# LPC18xx register map
File version: 18
Registers are 32-bit, read-write, reset 0x0 unless marked. A register's access mark holds for its fields unless they carry their own. Offsets are from the block's base; [hi:lo] are bit positions; {n}, {i} and the like mark numbered series; 'fields as' and 'values as' point back to an identical list.

## USB0 (part 2 of 2) — Product name title=UM10430 Chapter title=LPC18xx USB0 Host/Device/OTG controller Modification date=1/19/2011 Major revision=0 Minor revision=7
Base 0x40006000
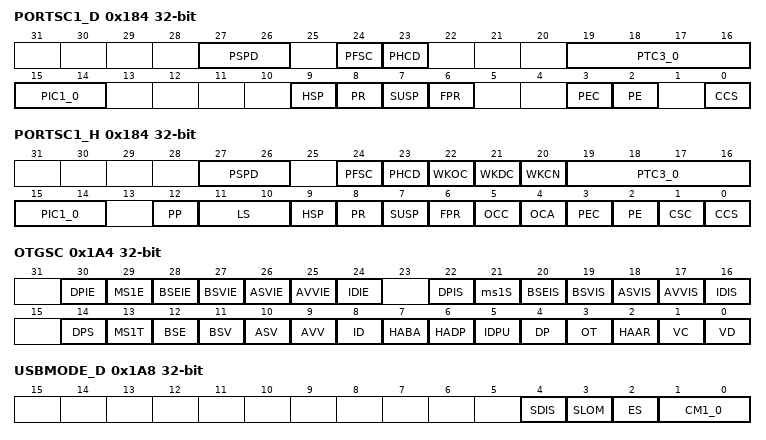
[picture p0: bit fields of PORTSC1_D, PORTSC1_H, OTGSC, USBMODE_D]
0x184 PORTSC1_D — Port 1 status/control (device mode)
  [27:26] PSPD — Port speed This register field indicates the speed at which the port is operating.
    0=FULL_SPEED; 1=INVALID_IN_DEVICE_MO (invalid in device mode); 2=HIGH_SPEED
  [24] PFSC — Port force full speed connect
    0=ANYSPEED (Port connects at any speed.); 1=FULLSPEED (Writing this bit to a 1 will force the port to only connect at full speed. It disables the chirp sequence that allows the port to identify itself as High-speed. This is useful for testing FS configurations with a HS host, hub or device.)
  [23] PHCD — PHY low power suspend - clock disable (PLPSCD) In device mode, The PHY can be put into Low Power Suspend - Clock Disable when the device is not running (USBCMD Run/Stop = 0) or the host has signaled suspend (PORTSC SUSPEND = 1). Low power suspend will be cleared automatically when the host has signaled resume. Before forcing a resume from the device, the device controller driver must clear this bit.
    0=ENABLE (Writing a 0 enables the PHY clock. Reading a 0 indicates the status of the PHY clock (enabled).); 1=DISABLE (Writing a 1 disables the PHY clock. Reading a 1 indicates the status of the PHY clock (disabled).)
  [19:16] PTC3_0 — Port test control Any value other than 0000 indicates that the port is operating in test mode. The FORCE_ENABLE_FS and FORCE ENABLE_LS are extensions to the test mode support specified in the EHCI specification. Writing the PTC field to any of the FORCE_ENABLE_HS/FS/LS values will force the port into the connected and enabled state at the selected speed. Writing the PTC field back to TEST_MODE_DISABLE will allow the port state machines to progress normally from that point. Values 0111 to 1111 are not valid.
    0=TEST_MODE_DISABLE; 1=J_STATE; 2=K_STATE; 3=SE0_(HOST)/NAK_(DEVI (SE0 (host)/NAK (device)); 4=PACKET; 5=FORCE_ENABLE_HS; 6=FORCE_ENABLE_FS
  [15:14] PIC1_0 — Port indicator control Writing to this field effects the value of the USB0_IND[1:0] pins.
    0=OFF (Port indicators are off.); 1=AMBER; 2=GREEN; 3=UNDEFINED
  [9] HSP — High-speed status This bit is redundant with bits 27:26 (PSPD) in this register. It is implemented for compatibility reasons.
    0=NOT_HIGHSSPEED (Host/device connected to the port is not in High-speed mode.); 1=HIGHSPEED (Host/device connected to the port is in High-speed mode.)
  [8] PR — Port reset In device mode, this is a read-only status bit. A device reset from the USB bus is also indicated in the USBSTS register.
    0=PORT_IS_NOT_IN_THE_R (Port is not in the reset state.); 1=PORT_IS_IN_THE_RESET (Port is in the reset state.)
  [7] SUSP — Suspend In device mode, this is a read-only status bit .
    0=PORT_NOT_IN_SUSPEND_ (Port not in suspend state); 1=PORT_IN_SUSPEND_STAT (Port in suspend state)
  [6] FPR — Force port resume After the device has been in Suspend State for 5 ms or more, software must set this bit to one to drive resume signaling before clearing. The Device Controller will set this bit to one if a J-to-K transition is detected while the port is in the Suspend state. The bit will be cleared when the device returns to normal operation. When this bit transitions to a one because a J-to-K transition detected, the Port Change Detect bit in the USBSTS register is set to one as well.
    0=NO_RESUME_(K_STATE)_ (No resume (K-state) detected/driven on port.); 1=RESUME_DETECTED/DRIV (Resume detected/driven on port.)
  [3] PEC — Port enable/disable change This bit is always 0. The device port is always enabled.
  [2] PE — Port enable. This bit is always 1. The device port is always enabled.
  [0] CCS — Current connect status
    0=DEVICE_NOT_ATTACHED_ (Device not attached A zero indicates that the device did not attach successfully or was forcibly disconnected by the software writing a zero to the Run bit in the USBCMD register. It does not state the device being disconnected or suspended.); 1=DEVICE_ATTACHED__A_ (Device attached. A one indicates that the device successfully attached and is operating in either high-speed mode or full-speed mode as indicated by the High Speed Port bit in this register.)
0x184 PORTSC1_H (alternate view of PORTSC1_D) — Port 1 status/control (host mode)
  [27:26] PSPD — Port speed This register field indicates the speed at which the port is operating. For HS mode operation in the host controller and HS/FS operation in the device controller the port routing steers data to the Protocol engine. For FS and LS mode operation in the host controller, the port routing steers data to the Protocol Engine w/ Embedded Transaction Translator.
    0=FULL_SPEED; 1=LOW_SPEED; 2=HIGH_SPEED
  [24] PFSC — Port force full speed connect
    0=PORT_CONNECTS_AT_ANY (Port connects at any speed.); 1=WRITING_THIS_BIT_TO_ (Writing this bit to a 1 will force the port to only connect at Full Speed. It disables the chirp sequence that allows the port to identify itself as High Speed. This is useful for testing FS configurations with a HS host, hub or device.)
  [23] PHCD — PHY low power suspend - clock disable (PLPSCD) In host mode, the PHY can be put into Low Power Suspend - Clock Disable when the downstream device has been put into suspend mode or when no downstream device is connected. Low power suspend is completely under the control of software.
    0=WRITING_A_0_ENABLES_ (Writing a 0 enables the PHY clock. Reading a 0 indicates the status of the PHY clock (enabled).); 1=WRITING_A_1_DISABLES (Writing a 1 disables the PHY clock. Reading a 1 indicates the status of the PHY clock (disabled).)
  [22] WKOC — Wake on over-current enable (WKOC_E)
    0=DISABLES_THE_PORT_TO (Disables the port to wake up on over-current events.); 1=WRITING_A_ONE_TO_THI (Writing a one to this bit enabled the port to be sensitive to over-current conditions as wake-up events.)
  [21] WKDC — Wake on disconnect enable (WKDSCNNT_E) This bit is 0 if PP (Port Power bit) is 0.
    0=DISABLES_THE_PORT_TO (Disables the port to wake up on device disconnects.); 1=WRITING_THIS_BIT_TO_ (Writing this bit to a one enables the port to be sensitive to device disconnects as wake-up events.)
  [20] WKCN — Wake on connect enable (WKCNNT_E) This bit is 0 if PP (Port Power bit) is 0
    0=DISABLES_THE_PORT_TO (Disables the port to wake up on device connects.); 1=WRITING_THIS_BIT_TO_ (Writing this bit to a one enables the port to be sensitive to device connects as wake-up events.)
  [19:16] PTC3_0 — Port test control Any value other than 0000 indicates that the port is operating in test mode. The FORCE_ENABLE_FS and FORCE ENABLE_LS are extensions to the test mode support specified in the EHCI specification. Writing the PTC field to any of the FORCE_ENABLE_{HS/FS/LS} values will force the port into the connected and enabled state at the selected speed. Writing the PTC field back to TEST_MODE_DISABLE will allow the port state machines to progress normally from that point. Values 0x8 to 0xF are reserved.
    0=TEST_MODE_DISABLE; 1=J_STATE; 2=K_STATE; 3=SE0_(HOST)/NAK_(DEVI (SE0 (host)/NAK (device)); 4=PACKET; 5=FORCE_ENABLE_HS; 6=FORCE_ENABLE_FS; 7=FORCE_ENABLE_LS
  [15:14] PIC1_0 — Port indicator control Writing to this field effects the value of the pins USB0_IND1 and USB0_IND0.
    0=PORT_INDICATORS_ARE_ (Port indicators are off.); 1=AMBER; 2=GREEN; 3=UNDEFINED
  [12] PP — Port power control Host/OTG controller requires port power control switches. This bit represents the current setting of the switch (0=off, 1=on). When power is not available on a port (i.e. PP equals a 0), the port is non-functional and will not report attaches, detaches, etc. When an over-current condition is detected on a powered port and PPC is a one, the PP bit in each affected port may be transitioned by the host controller driver from a one to a zero (removing power from the port).
    0=PORT_POWER_OFF_; 1=PORT_POWER_ON_
  [11:10] LS — Line status These bits reflect the current logical levels of the USB_DP and USB_DM signal lines. USB_DP corresponds to bit 11 and USB_DM to bit 10. In host mode, the use of linestate by the host controller driver is not necessary for this controller (unlike EHCI) because the controller hardware manages the connection of LS and FS.
    0=SE0_(USB_DP_AND_USB_ (SE0 (USB_DP and USB_DM LOW)); 1=J_STATE_(USB_DP_HIGH (J-state (USB_DP HIGH and USB_DM LOW)); 2=K_STATE_(USB_DP_LOW_ (K-state (USB_DP LOW and USB_DM HIGH)); 3=UNDEFINED
  [9] HSP — High-speed status
    0=HOST/DEVICE_CONNECTE (Host/device connected to the port is not in High-speed mode.); 1=HOST/DEVICE_CONNECTE (Host/device connected to the port is in High-speed mode.)
  [8] PR — Port reset When software writes a one to this bit the bus-reset sequence as defined in the USB Specification Revision 2.0 is started. This bit will automatically change to zero after the reset sequence is complete. This behavior is different from EHCI where the host controller driver is required to set this bit to a zero after the reset duration is timed in the driver. This bit is 0 if PP (Port Power bit) is 0.
    values as PORTSC1_D.PR
  [7] SUSP — Suspend Together with the PE (Port enabled bit), this bit describes the port states, see Table 240. The host controller will unconditionally set this bit to zero when software sets the Force Port Resume bit to zero. The host controller ignores a write of zero to this bit. If host software sets this bit to a one when the port is not enabled (i.e. Port enabled bit is a zero) the results are undefined. This bit is 0 if PP (Port Power bit) is 0.
    0=PORT_NOT_IN_SUSPEND_ (Port not in suspend state); 1=PORT_IN_SUSPEND_STAT (Port in suspend state When in suspend state, downstream propagation of data is blocked on this port, except for port reset. The blocking occurs at the end of the current transaction if a transaction was in progress when this bit was written to 1. In the suspend state, the port is sensitive to resume detection. Note that the bit status does not change until the port is suspended and that there may be a delay in suspending a port if there is a transaction currently in progress on the USB.)
  [6] FPR — Force port resume Software sets this bit to one to drive resume signaling. The Host Controller sets this bit to one if a J-to-K transition is detected while the port is in the Suspend state. When this bit transitions to a one because a J-to-K transition is detected, the Port Change Detect bit in the USBSTS register is also set to one. This bit will automatically change to zero after the resume sequence is complete. This behavior is different from EHCI where the host controller driver is required to set this bit to a zero after the resume duration is timed in the driver. Note that when the Host controller owns the port, the resume sequence follows the defined sequence documented in the USB Specification Revision 2.0. The resume signaling (Full-speed K) is driven on the port as long as this bit remains a one. This bit will remain a one until the port has switched to the high-speed idle. Writing a zero has no affect because the port controller will time the resume operation clear the bit the port control state switches to HS or FS idle. This bit is 0 if PP (Port Power bit) is 0.
    values as PORTSC1_D.FPR
  [5] OCC — Over-current change This bit gets set to one when there is a change to Over-current Active. Software clears this bit by writing a one to this bit position.
  [4] OCA — Over-current active This bit will automatically transition from 1 to 0 when the over-current condition is removed.
    0=THE_PORT_DOES_NOT_HA (The port does not have an over-current condition.); 1=THE_PORT_HAS_CURRENT (The port has currently an over-current condition.)
  [3] PEC — Port disable/enable change For the root hub, this bit gets set to a one only when a port is disabled due to disconnect on the port or due to the appropriate conditions existing at the EOF2 point (See Chapter 11 of the USB Specification). Software clears this by writing a one to it. This bit is 0 if PP (Port Power bit) is 0,
    0=NO_CHANGE_; 1=PORT_ENABLED/DISABLE (Port enabled/disabled status has changed.)
  [2] PE — Port enable. Ports can only be enabled by the host controller as a part of the reset and enable. Software cannot enable a port by writing a one to this field. Ports can be disabled by either a fault condition (disconnect event or other fault condition) or by the host software. Note that the bit status does not change until the port state actually changes. There may be a delay in disabling or enabling a port due to other host controller and bus events. When the port is disabled. downstream propagation of data is blocked except for reset. This bit is 0 if PP (Port Power bit) is 0.
    0=PORT_DISABLED_; 1=PORT_ENABLED_
  [1] CSC — Connect status change Indicates a change has occurred in the port's Current Connect Status. The host/device controller sets this bit for all changes to the port device connect status, even if system software has not cleared an existing connect status change. For example, the insertion status changes twice before system software has cleared the changed condition, hub hardware will be setting an already-set bit (i.e., the bit will remain set). Software clears this bit by writing a one to it. This bit is 0 if PP (Port Power bit) is 0
    0=NO_CHANGE_IN_CURRENT (No change in current status.); 1=CHANGE_IN_CURRENT_ST (Change in current status.)
  [0] CCS — Current connect status This value reflects the current state of the port and may not correspond directly to the event that caused the CSC bit to be set. This bit is 0 if PP (Port Power bit) is 0. Software clears this bit by writing a 1 to it.
    0=NO_DEVICE_IS_PRESENT; 1=DEVICE_IS_PRESENT_ON (Device is present on the port.)
0x1A4 OTGSC — OTG status and control
  [30] DPIE — Data pulse interrupt enable Setting this bit enables the data pulse interrupt. Writing a 0 disables the interrupt
  [29] MS1E — 1 millisecond timer interrupt enable Setting this bit enables the 1 millisecond timer interrupt. Writing a 0 disables the interrupt.
  [28] BSEIE — B-session end interrupt enable Setting this bit enables the B-session end interrupt. Writing a 0 disables the interrupt.
  [27] BSVIE — B-session valid interrupt enable Setting this bit enables the B-session valid interrupt. Writing a 0 disables the interrupt.
  [26] ASVIE — A-session valid interrupt enable Setting this bit enables the A-session valid interrupt. Writing a 0 disables the interrupt
  [25] AVVIE — A-VBUS valid interrupt enable Setting this bit enables the A-VBUS valid interrupt. Writing a 0 disables the interrupt.
  [24] IDIE — USB ID interrupt enable Setting this bit enables the interrupt. Writing a 0 disables the interrupt.
  [22] DPIS — Data pulse interrupt status This bit is set when data bus pulsing occurs on DP or DM. Data bus pulsing is only detected when the CM bit in USBMODE = Host (11) and the PortPower bit in PORTSC = Off (0). Software must write a 1 to this bit to clear it.
  [21] ms1S — 1 millisecond timer interrupt status This bit is set once every millisecond. Software must write a 1 to this bit to clear it.
  [20] BSEIS — B-Session end interrupt status This bit is set then VBUS has fallen below the B-session end threshold. Software must write a 1 to this bit to clear it.
  [19] BSVIS — B-Session valid interrupt status This bit is set then VBUS has either risen above or fallen below the B-session valid threshold (0.8 V). Software must write a 1 to this bit to clear it.
  [18] ASVIS — A-Session valid interrupt status This bit is set then VBUS has either risen above or fallen below the A-session valid threshold (0.8 V). Software must write a 1 to this bit to clear it.
  [17] AVVIS — A-VBUS valid interrupt status This bit is set then VBUS has either risen above or fallen below the A-VBUS valid threshold (4.4 V on an A-device). Software must write a 1 to this bit to clear it.
  [16] IDIS — USB ID interrupt status This bit is set when a change on the ID input has been detected. Software must write a 1 to this bit to clear it.
  [14] DPS — Data bus pulsing status Reading a 1 indicates that data bus pulsing is detected on the port.
  [13] MS1T — 1 millisecond timer toggle This bit toggles once per millisecond.
  [12] BSE — B-session end Reading 1 indicates that VBUS is below the B-session end threshold.
  [11] BSV — B-session valid Reading 1 indicates that VBUS is above the B-session valid threshold.
  [10] ASV — A-session valid Reading 1 indicates that VBUS is above the A-session valid threshold.
  [9] AVV — A-VBUS valid Reading 1 indicates that VBUS is above the A-VBUS valid threshold.
  [8] ID — USB ID
    0=A_DEVICE; 1=B_DEVICE
  [7] HABA — Hardware assist B-disconnect to A-connect
    0=DISABLED_; 1=ENABLE_AUTOMATIC_B_D (Enable automatic B-disconnect to A-connect sequence.)
  [6] HADP — Hardware assist data pulse Write a 1 to start data pulse sequence.
  [5] IDPU — ID pull-up. This bit provides control over the pull-up resistor.
    0=PULL_UP_OFF_THE_ID_ (Pull-up off. The ID bit will not be sampled.); 1=PULL_UP_ON_
  [4] DP — Data pulsing Setting this bit to 1 causes the pull-up on USB_DP to be asserted for data pulsing during SRP.
  [3] OT — OTG termination This bit must be set to 1 when the OTG controller is in device mode. This controls the pull-down on USB_DM.
  [2] HAAR — Hardware assist auto_reset
    0=DISABLED; 1=ENABLE_AUTOMATIC_RES (Enable automatic reset after connect on host port.)
  [1] VC — VBUS_Charge Setting this bit to 1 causes the VBUS line to be charged. This is used for VBUS pulsing during SRP.
  [0] VD — VBUS_Discharge Setting this bit to 1 causes VBUS to discharge through a resistor.
0x1A8 USBMODE_D — USB device mode (device mode)
  [4] SDIS — Stream disable mode The use of this feature substantially limits the overall USB performance that can be achieved.
    0=NOT_DISABLED; 1=DISABLED_SETTING_TH (Disabled. Setting this bit to one disables double priming on both RX and TX for low bandwidth systems. This mode ensures that when the RX and TX buffers are sufficient to contain an entire packet that the standard double buffering scheme is disabled to prevent overruns/underruns in bandwidth limited systems. Note: In High Speed Mode, all packets received will be responded to with a NYET handshake when stream disable is active.)
  [3] SLOM — Setup Lockout mode In device mode, this bit controls behavior of the setup lock mechanism. See Section 18.10.8.
    0=SETUP_LOCKOUTS_ON; 1=SETUP_LOCKOUTS_OFF_( (Setup Lockouts Off (DCD requires the use of Setup Buffer Tripwire in USBCMD))
  [2] ES — Endian select This bit can change the byte ordering of the transfer buffers to match the host microprocessor bus architecture. The bit fields in the microprocessor interface and the DMA data structures (including the setup buffer within the device QH) are unaffected by the value of this bit, because they are based upon 32-bit words.
    0=LITTLE_ENDIAN_FIRST (Little endian: first byte referenced in least significant byte of 32-bit word.); 1=BIG_ENDIAN_FIRST_BY (Big endian: first byte referenced in most significant byte of 32-bit word.)
  [1:0] CM1_0 — Controller mode The controller defaults to an idle state and needs to be initialized to the desired operating mode after reset. This register can only be written once after reset. If it is necessary to switch modes, software must reset the controller by writing to the RESET bit in the USBCMD register before reprogramming this register.
    0=IDLE; 2=DEVICE_CONTROLLER; 3=HOST_CONTROLLER
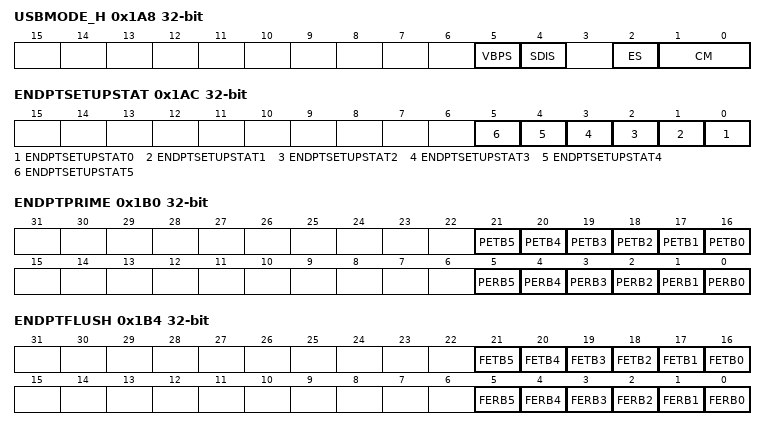
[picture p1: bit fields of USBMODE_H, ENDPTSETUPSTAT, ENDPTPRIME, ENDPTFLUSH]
0x1A8 USBMODE_H (alternate view of USBMODE_D) — USB mode (host mode)
  [5] VBPS — VBUS power select
    0=LOW (vbus_pwr_select is set LOW.); 1=HIGH (vbus_pwr_select is set HIGH)
  [4] SDIS — Stream disable mode The use of this feature substantially limits the overall USB performance that can be achieved.
    0=NOT_DISABLED; 1=DISABLED_SETTING_TO (Disabled. Setting to a 1 ensures that overruns/underruns of the latency FIFO are eliminated for low bandwidth systems where the RX and TX buffers are sufficient to contain the entire packet. Enabling stream disable also has the effect of ensuring the the TX latency is filled to capacity before the packet is launched onto the USB. Note: Time duration to pre-fill the FIFO becomes significant when stream disable is active. See TXFILLTUNING to characterize the adjustments needed for the scheduler when using this feature.)
  [2] ES — Endian select This bit can change the byte ordering of the transfer buffers. The bit fields in the microprocessor interface and the DMA data structures (including the setup buffer within the device QH) are unaffected by the value of this bit, because they are based upon 32-bit words.
    values as USBMODE_D.ES
  [1:0] CM — Controller mode The controller defaults to an idle state and needs to be initialized to the desired operating mode after reset. This register can only be written once after reset. If it is necessary to switch modes, software must reset the controller by writing to the RESET bit in the USBCMD register before reprogramming this register.
    0=IDLE; 2=DEVICE_CONTROLLER; 3=HOST_CONTROLLER
0x1AC ENDPTSETUPSTAT — Endpoint setup status
  [n] ENDPTSETUPSTAT{n} (n=0..5) — Setup endpoint status for logical endpoints 0 to 5. For every setup transaction that is received, a corresponding bit in this register is set to one. Software must clear or acknowledge the setup transfer by writing a one to a respective bit after it has read the setup data from Queue head. The response to a setup packet as in the order of operations and total response time is crucial to limit bus time outs while the setup lockout mechanism is engaged.
0x1B0 ENDPTPRIME — Endpoint initialization
  [n+16] PETB{n} (n=0..5) — Prime endpoint transmit buffer for physical IN endpoints 5 to 0. For each IN endpoint a corresponding bit is set to one by software to request a buffer be prepared for a transmit operation in order to respond to a USB IN/INTERRUPT transaction. Software should write a one to the corresponding bit when posting a new transfer descriptor to an endpoint. Hardware will automatically use this bit to begin parsing for a new transfer descriptor from the queue head and prepare a transmit buffer. Hardware will clear this bit when the associated endpoint(s) is (are) successfully primed. PETB0 = endpoint 0 ... PETB5 = endpoint 5
  [n] PERB{n} (n=0..5) — Prime endpoint receive buffer for physical OUT endpoints 5 to 0. For each OUT endpoint, a corresponding bit is set to 1 by software to request a buffer be prepared for a receive operation for when a USB host initiates a USB OUT transaction. Software should write a one to the corresponding bit whenever posting a new transfer descriptor to an endpoint. Hardware will automatically use this bit to begin parsing for a new transfer descriptor from the queue head and prepare a receive buffer. Hardware will clear this bit when the associated endpoint(s) is (are) successfully primed. PERB0 = endpoint 0 ... PERB5 = endpoint 5
0x1B4 ENDPTFLUSH — Endpoint de-initialization
  [n+16] FETB{n} (n=0..5) — Flush endpoint transmit buffer for physical IN endpoints 5 to 0. Writing a one to a bit(s) will clear any primed buffers. FETB0 = endpoint 0 ... FETB5 = endpoint 5
  [n] FERB{n} (n=0..5) — Flush endpoint receive buffer for physical OUT endpoints 5 to 0. Writing a one to a bit(s) will clear any primed buffers. FERB0 = endpoint 0 ... FERB5 = endpoint 5
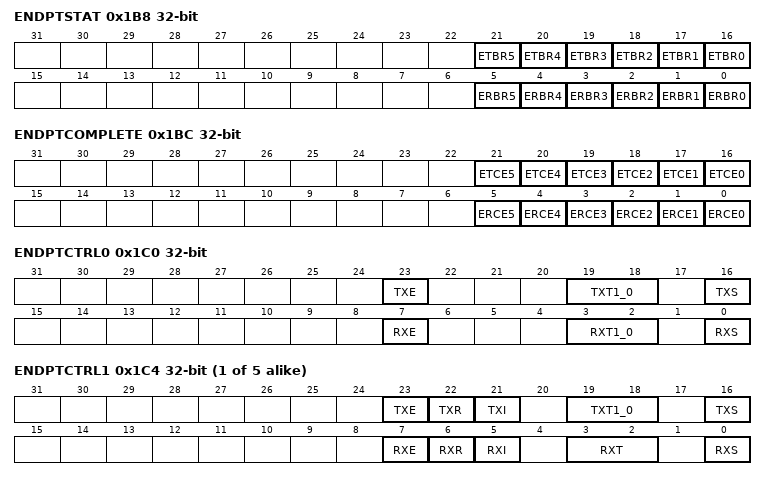
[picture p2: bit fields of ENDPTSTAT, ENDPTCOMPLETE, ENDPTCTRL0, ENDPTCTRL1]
0x1B8 ENDPTSTAT ro — Endpoint status
  [n+16] ETBR{n} (n=0..5) — Endpoint transmit buffer ready for physical IN endpoints 3 to 0. This bit is set to 1 by hardware as a response to receiving a command from a corresponding bit in the ENDPTPRIME register. ETBR0 = endpoint 0 ... ETBR5 = endpoint 5
  [n] ERBR{n} (n=0..5) — Endpoint receive buffer ready for physical OUT endpoints 5 to 0. This bit is set to 1 by hardware as a response to receiving a command from a corresponding bit in the ENDPTPRIME register. ERBR0 = endpoint 0 ... ERBR5 = endpoint 5
0x1BC ENDPTCOMPLETE — Endpoint complete
  [n+16] ETCE{n} (n=0..5) — Endpoint transmit complete event for physical IN endpoints 5 to 0. This bit is set to 1 by hardware when a transmit event (IN/INTERRUPT) occurred. ETCE0 = endpoint 0 ... ETCE5 = endpoint 5
  [n] ERCE{n} (n=0..5) — Endpoint receive complete event for physical OUT endpoints 5 to 0. This bit is set to 1 by hardware when receive event (OUT/SETUP) occurred. ERCE0 = endpoint 0 ... ERCE5 = endpoint 5
0x1C0 ENDPTCTRL0 — Endpoint control 0
  [23] TXE — Tx endpoint enable Endpoint enabled. Control endpoint 0 is always enabled. This bit is always 1.
  [19:18] TXT1_0 — Endpoint type Endpoint 0 is always a control endpoint.
  [16] TXS — Tx endpoint stall
    0=ENDPOINT_OK_; 1=ENDPOINT_STALLED_SOF (Endpoint stalled Software can write a one to this bit to force the endpoint to return a STALL handshake to the Host. It will continue returning STALL until the bit is cleared by software, or it will automatically be cleared upon receipt of a new SETUP request. After receiving a SETUP request, this bit will continue to be cleared by hardware until the associated ENDSETUPSTAT bit is cleared.[1])
  [7] RXE — Rx endpoint enable Endpoint enabled. Control endpoint 0 is always enabled. This bit is always 1.
  [3:2] RXT1_0 — Endpoint type Endpoint 0 is always a control endpoint.
  [0] RXS — Rx endpoint stall
    values as TXS
{0x1C0+4i} ENDPTCTRL{i} (i=1..5) — Endpoint control
  [23] TXE — Tx endpoint enable An endpoint should be enabled only after it has been configured
    0=ENDPOINT_DISABLED_; 1=ENDPOINT_ENABLED_
  [22] TXR — Tx data toggle reset Write 1 to reset the PID sequence. Whenever a configuration event is received for this Endpoint, software must write a one to this bit in order to synchronize the data PIDs between the host and device.
  [21] TXI — Tx data toggle inhibit This bit is only used for test and should always be written as zero. Writing a one to this bit will cause this endpoint to ignore the data toggle sequence and always accept data packets regardless of their data PID.
    0=ENABLED; 1=DISABLED
  [19:18] TXT1_0 — Tx endpoint type
    0=CONTROL; 1=ISOCHRONOUS; 2=BULK; 3=INTERRUPT
  [16] TXS — Tx endpoint stall
    0=ENDPOINT_OK_THIS_BI (Endpoint ok. This bit will be cleared automatically upon receipt of a SETUP request if this Endpoint is configured as a Control Endpoint, and this bit will continue to be cleared by hardware until the associated ENDPTSETUPSTAT bit is cleared.); 1=ENDPOINT_STALLED_SOF (Endpoint stalled Software can write a one to this bit to force the endpoint to return a STALL handshake to the Host. It will continue returning STALL until the bit is cleared by software, or it will automatically be cleared upon receipt of a new SETUP request.)
  [7] RXE — Rx endpoint enable An endpoint should be enabled only after it has been configured.
    0=ENDPOINT_DISABLED_; 1=ENDPOINT_ENABLED_
  [6] RXR — Rx data toggle reset Write 1 to reset the PID sequence. Whenever a configuration event is received for this Endpoint, software must write a one to this bit in order to synchronize the data PIDs between the host and device.
  [5] RXI — Rx data toggle inhibit This bit is only used for test and should always be written as zero. Writing a one to this bit will cause this endpoint to ignore the data toggle sequence and always accept data packets regardless of their data PID.
    0=DISABLED; 1=ENABLED
  [3:2] RXT — Endpoint type
    0=CONTROL; 1=ISOCHRONOUS; 2=BULK
  [0] RXS — Rx endpoint stall
    0=ENDPOINT_OK_THIS_BI (Endpoint ok. This bit will be cleared automatically upon receipt of a SETUP request if this Endpoint is configured as a Control Endpoint and this bit will continue to be cleared by hardware until the associated ENDPTSETUPSTAT bit is cleared.); 1=ENDPOINT_STALLED_SOF (Endpoint stalled Software can write a one to this bit to force the endpoint to return a STALL handshake to the Host. It will continue returning STALL until the bit is cleared by software, or it will automatically be cleared upon receipt of a new SETUP request.)
